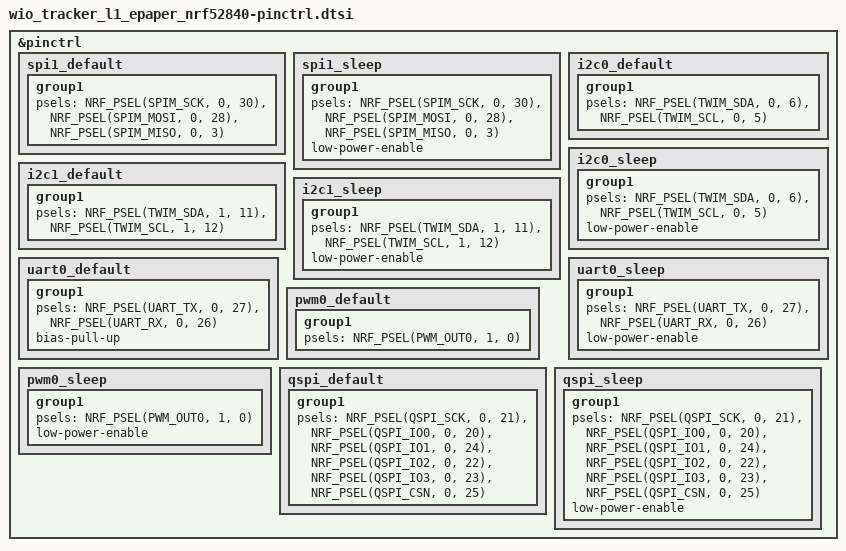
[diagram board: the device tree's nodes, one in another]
/*
 * Seeed Wio Tracker L1 pin control definitions (ePaper variant)
 * Copyright (c) 2025 ZephCore
 *
 * SPDX-License-Identifier: Apache-2.0
 */

&pinctrl {
	/* SPI1 for LoRa SX1262 and SSD1680 ePaper display */
	spi1_default: spi1_default {
		group1 {
			psels = <NRF_PSEL(SPIM_SCK, 0, 30)>,
				<NRF_PSEL(SPIM_MOSI, 0, 28)>,
				<NRF_PSEL(SPIM_MISO, 0, 3)>;
		};
	};

	spi1_sleep: spi1_sleep {
		group1 {
			psels = <NRF_PSEL(SPIM_SCK, 0, 30)>,
				<NRF_PSEL(SPIM_MOSI, 0, 28)>,
				<NRF_PSEL(SPIM_MISO, 0, 3)>;
			low-power-enable;
		};
	};

	/* I2C0 for sensors */
	i2c0_default: i2c0_default {
		group1 {
			psels = <NRF_PSEL(TWIM_SDA, 0, 6)>,
				<NRF_PSEL(TWIM_SCL, 0, 5)>;
		};
	};

	i2c0_sleep: i2c0_sleep {
		group1 {
			psels = <NRF_PSEL(TWIM_SDA, 0, 6)>,
				<NRF_PSEL(TWIM_SCL, 0, 5)>;
			low-power-enable;
		};
	};

	/* I2C1 for Grove connector */
	i2c1_default: i2c1_default {
		group1 {
			psels = <NRF_PSEL(TWIM_SDA, 1, 11)>,
				<NRF_PSEL(TWIM_SCL, 1, 12)>;
		};
	};

	i2c1_sleep: i2c1_sleep {
		group1 {
			psels = <NRF_PSEL(TWIM_SDA, 1, 11)>,
				<NRF_PSEL(TWIM_SCL, 1, 12)>;
			low-power-enable;
		};
	};

	/* UART0 for GPS L76KB at 9600 baud */
	uart0_default: uart0_default {
		group1 {
			psels = <NRF_PSEL(UART_TX, 0, 27)>,
				<NRF_PSEL(UART_RX, 0, 26)>;
			bias-pull-up;
		};
	};

	uart0_sleep: uart0_sleep {
		group1 {
			psels = <NRF_PSEL(UART_TX, 0, 27)>,
				<NRF_PSEL(UART_RX, 0, 26)>;
			low-power-enable;
		};
	};

	/* PWM0 for buzzer on P1.00 */
	pwm0_default: pwm0_default {
		group1 {
			psels = <NRF_PSEL(PWM_OUT0, 1, 0)>;
		};
	};

	pwm0_sleep: pwm0_sleep {
		group1 {
			psels = <NRF_PSEL(PWM_OUT0, 1, 0)>;
			low-power-enable;
		};
	};

	/* QSPI for external flash */
	qspi_default: qspi_default {
		group1 {
			psels = <NRF_PSEL(QSPI_SCK, 0, 21)>,
				<NRF_PSEL(QSPI_IO0, 0, 20)>,
				<NRF_PSEL(QSPI_IO1, 0, 24)>,
				<NRF_PSEL(QSPI_IO2, 0, 22)>,
				<NRF_PSEL(QSPI_IO3, 0, 23)>,
				<NRF_PSEL(QSPI_CSN, 0, 25)>;
		};
	};

	qspi_sleep: qspi_sleep {
		group1 {
			psels = <NRF_PSEL(QSPI_SCK, 0, 21)>,
				<NRF_PSEL(QSPI_IO0, 0, 20)>,
				<NRF_PSEL(QSPI_IO1, 0, 24)>,
				<NRF_PSEL(QSPI_IO2, 0, 22)>,
				<NRF_PSEL(QSPI_IO3, 0, 23)>,
				<NRF_PSEL(QSPI_CSN, 0, 25)>;
			low-power-enable;
		};
	};
};
